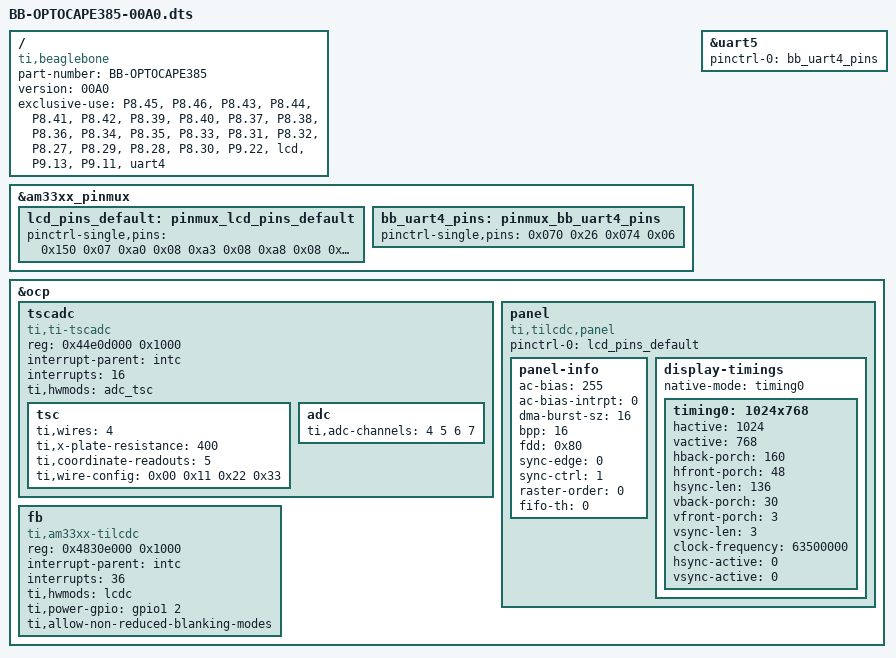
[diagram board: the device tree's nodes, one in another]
/*
 * OPTOCAPE BeagleBone Black Cape
 * 3.8 Kernel
 * XGA LCD Panel
 * 400 ohm 4-wire resistive touch
 */

/dts-v1/;
/plugin/;

/ {
	compatible = "ti,beaglebone", "ti,beaglebone-black", "ti,beaglebone-green";

	/* identification */
	part-number = "BB-OPTOCAPE385";
	version = "00A0";

	/* state the resources this cape uses */
	exclusive-use =
		/* the pin header uses */
		"P8.45",	/* lcd: lcd_data0 */
		"P8.46",	/* lcd: lcd_data1 */
		"P8.43",	/* lcd: lcd_data2 */
		"P8.44",	/* lcd: lcd_data3 */
		"P8.41",	/* lcd: lcd_data4 */
		"P8.42",	/* lcd: lcd_data5 */
		"P8.39",	/* lcd: lcd_data6 */
		"P8.40",	/* lcd: lcd_data7 */
		"P8.37",	/* lcd: lcd_data8 */
		"P8.38",	/* lcd: lcd_data9 */
		"P8.36",	/* lcd: lcd_data10 */
		"P8.34",	/* lcd: lcd_data11 */
		"P8.35",	/* lcd: lcd_data12 */
		"P8.33",	/* lcd: lcd_data13 */
		"P8.31",	/* lcd: lcd_data14 */
		"P8.32",	/* lcd: lcd_data15 */
		"P8.27",	/* lcd: lcd_vsync */
		"P8.29",	/* lcd: lcd_hsync */
		"P8.28",	/* lcd: lcd_pclk */
		"P8.30",	/* lcd: lcd_ac_bias_en */
		"P9.22", /* lcd: gpio0_2 */

		"lcd",
		/* the pin header uses */
		"P9.13",	/* uart4_txd */
		"P9.11",	/* uart4_rxd */
		/* the hardware ip uses */
		"uart4";

	fragment@0 {
		target = <&am33xx_pinmux>;
		__overlay__ {

			lcd_pins_default: pinmux_lcd_pins_default {
				pinctrl-single,pins = <
					0x150 0x07	/* spi0_sclk.gpio0_2, OUTPUT | MODE7 - AVDD_EN */
					0xa0 0x08	/* lcd_data0.lcd_data0, OMAP_MUX_MODE0 | AM33XX_PIN_OUTPUT | AM33XX_PULL_DISA */
					0xa3 0x08	/* lcd_data1.lcd_data1, OMAP_MUX_MODE0 | AM33XX_PIN_OUTPUT | AM33XX_PULL_DISA */
					0xa8 0x08	/* lcd_data2.lcd_data2, OMAP_MUX_MODE0 | AM33XX_PIN_OUTPUT | AM33XX_PULL_DISA */
					0xac 0x08	/* lcd_data3.lcd_data3, OMAP_MUX_MODE0 | AM33XX_PIN_OUTPUT | AM33XX_PULL_DISA */
					0xb0 0x08	/* lcd_data3.lcd_data3, OMAP_MUX_MODE0 | AM33XX_PIN_OUTPUT | AM33XX_PULL_DISA */
					0xb4 0x08	/* lcd_data5.lcd_data5, OMAP_MUX_MODE0 | AM33XX_PIN_OUTPUT | AM33XX_PULL_DISA */
					0xb8 0x08	/* lcd_data6.lcd_data6, OMAP_MUX_MODE0 | AM33XX_PIN_OUTPUT | AM33XX_PULL_DISA */
					0xbc 0x08	/* lcd_data7.lcd_data7, OMAP_MUX_MODE0 | AM33XX_PIN_OUTPUT | AM33XX_PULL_DISA */
					0xc0 0x08	/* lcd_data8.lcd_data8, OMAP_MUX_MODE0 | AM33XX_PIN_OUTPUT | AM33XX_PULL_DISA */
					0xc4 0x08	/* lcd_data9.lcd_data9, OMAP_MUX_MODE0 | AM33XX_PIN_OUTPUT | AM33XX_PULL_DISA */
					0xc8 0x08	/* lcd_data10.lcd_data10, OMAP_MUX_MODE0 | AM33XX_PIN_OUTPUT | AM33XX_PULL_DISA */
					0xcc 0x08	/* lcd_data11.lcd_data11, OMAP_MUX_MODE0 | AM33XX_PIN_OUTPUT | AM33XX_PULL_DISA */
					0xd0 0x08	/* lcd_data12.lcd_data12, OMAP_MUX_MODE0 | AM33XX_PIN_OUTPUT | AM33XX_PULL_DISA */
					0xd4 0x08	/* lcd_data13.lcd_data13, OMAP_MUX_MODE0 | AM33XX_PIN_OUTPUT | AM33XX_PULL_DISA */
					0xd8 0x08	/* lcd_data14.lcd_data14, OMAP_MUX_MODE0 | AM33XX_PIN_OUTPUT | AM33XX_PULL_DISA */
					0xdc 0x08	/* lcd_data15.lcd_data15, OMAP_MUX_MODE0 | AM33XX_PIN_OUTPUT | AM33XX_PULL_DISA */
					0xe0 0x00	/* lcd_vsync.lcd_vsync, OMAP_MUX_MODE0 | AM33XX_PIN_OUTPUT */
					0xe4 0x00	/* lcd_hsync.lcd_hsync, OMAP_MUX_MODE0 | AM33XX_PIN_OUTPUT */
					0xe8 0x00	/* lcd_pclk.lcd_pclk, OMAP_MUX_MODE0 | AM33XX_PIN_OUTPUT */
					0xec 0x00	/* lcd_ac_bias_en.lcd_ac_bias_en, OMAP_MUX_MODE0 | AM33XX_PIN_OUTPUT */
				>;
			};

			bb_uart4_pins: pinmux_bb_uart4_pins {
				pinctrl-single,pins = <
					0x070 0x26	/* gpmc_wait0.uart4_rxd | MODE6 */
					0x074 0x06	/* gpmc_wpn.uart4_txd | MODE6 */
				>;
			};
		};
	};


	fragment@1 {
		target = <&uart5>;	/* really uart4 */
		__overlay__ {
			status = "okay";
			pinctrl-names = "default";
			pinctrl-0 = <&bb_uart4_pins>;
		};
	};

	fragment@2 {
		target = <&ocp>;
		__overlay__ {

			/* avoid stupid warning */
			#address-cells = <1>;
			#size-cells = <1>;

			tscadc {
				compatible = "ti,ti-tscadc";
				reg = <0x44e0d000 0x1000>;

				interrupt-parent = <&intc>;
				interrupts = <16>;
				ti,hwmods = "adc_tsc";
				status = "okay";

				tsc {
					ti,wires = <4>;
					ti,x-plate-resistance = <400>;
					ti,coordinate-readouts = <5>;
					ti,wire-config = <0x00 0x11 0x22 0x33>;
				};

				adc {
					ti,adc-channels = <4 5 6 7>;
				};
			};

			panel {
				compatible = "ti,tilcdc,panel";
				pinctrl-names = "default";
				pinctrl-0 = <&lcd_pins_default>;
				panel-info {
					ac-bias           = <255>;
					ac-bias-intrpt    = <0>;
					dma-burst-sz      = <16>;
					bpp               = <16>;
					fdd               = <0x80>;
					sync-edge         = <0>;
					sync-ctrl         = <1>;
					raster-order      = <0>;
					fifo-th           = <0>;
				};
				display-timings {
					native-mode = <&timing0>;
					timing0: 1024x768 {
						hactive         = <1024>;
						vactive         = <768>;
						hback-porch     = <160>;
						hfront-porch    = <48>;
						hsync-len       = <136>;
						vback-porch     = <30>;
						vfront-porch    = <3>;
						vsync-len       = <3>;
						clock-frequency = <63500000>;
						hsync-active    = <0>;
						vsync-active    = <0>;
					};
				};
			};

			fb {
				compatible = "ti,am33xx-tilcdc";
				reg = <0x4830e000 0x1000>;
				interrupt-parent = <&intc>;
				interrupts = <36>;
				ti,hwmods = "lcdc";
				ti,power-gpio = <&gpio1 2 0x0>;
				status = "okay";
				ti,allow-non-reduced-blanking-modes;
			};

		};
	};
};
